# NANO100AN_v1 register map
File version: 1.0
Registers are 32-bit, read-write, reset 0x0 unless marked. A register's access mark holds for its fields unless they carry their own. Offsets are from the block's base; [hi:lo] are bit positions; {n}, {i} and the like mark numbered series; 'fields as' and 'values as' point back to an identical list.

## ADC — ADC Register Map
Base 0x400E0000
{0x0+4i} ADC_RESULT{i} ro (i=0..7) — A/D Result Register {i}
  [11:0] RSLT — A/D Conversion Result. This field contains 12 bits conversion result.
0x28 ADC_RESULT10 ro — A/D Result Register 10
  fields as ADC_RESULT0
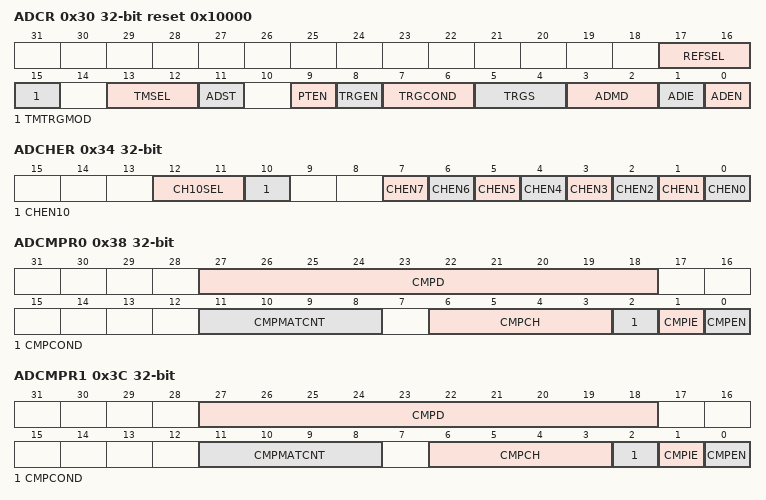
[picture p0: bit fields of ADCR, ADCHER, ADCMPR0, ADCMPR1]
0x30 ADCR reset 0x10000 — A/D Control Register
  [17:16] REFSEL — Reference Voltage Source Selection
    0=Select power as reference voltage; 1=Select VBG as reference voltage; 2=Select external voltage as reference voltage; 3=Ch7
  [15] TMTRGMOD — Timer Event Trigger ADC Conversion setting TMSEL to select timer event from timer0~3
    0=This function Disabled; 1=ADC Enabled by TIMER out event
  [13:12] TMSEL — Select A/D Enable Time-Out Source
    {v}=TMR{v} (v=0..3)
  [11] ADST — A/D Conversion Start. ADST bit can be set to 1 from two sources: software write and external pin STADC. ADST is cleared to 0 by hardware automatically at the end of single mode and single-cycle scan mode on specified channels. In continuous scan mode, A/D conversion is continuously performed sequentially unless software writes 0 to this bit or chip reset. Note: After ADC conversion done, SW needs to wait at least one ADC clock before to set this bit high again.
    0=Conversion stopped and A/D converter enter idle state; 1=Conversion starts
  [9] PTEN — PDMA Transfer Enable
    0=PDMA data transfer Disabled; 1=PDMA data transfer in ADC_RESULT 0~10 Enabled
  [8] TRGEN — External Trigger Enable. Enable or disable triggering of A/D conversion by external STADC pin.
    0=Disabled; 1=Enabled
  [7:6] TRGCOND — External Trigger Condition. These two bits decide external pin STADC trigger event is level or edge. The signal must be kept at stable state at least 8 PCLKs for level trigger and 4 PCLKs at high and low state.
    0=Low level; 1=High level; 2=Falling edge; 3=Rising edge
  [5:4] TRGS — Hardware Trigger Source. Software should disable TRGE and ADST before change TRGS. In hardware trigger mode, the ADST bit is set by the external trigger from STADC, However software has the highest priority to set or cleared ADST bit at any time.
    0=A/D conversion is started by external STADC pin
  [3:2] ADMD — A/D Converter Operation Mode
    0=Single conversion; 2=Single-cycle scan; 3=Continuous scan
  [1] ADIE — A/D Interrupt Enable. A/D conversion end interrupt request is generated if ADIE bit is set to 1.
    0=A/D interrupt function Disabled; 1=A/D interrupt function Enabled
  [0] ADEN — A/D Converter Enable. Before starting A/D conversion function, this bit should be set to 1. Clear it to 0 to disable A/D converter analog circuit power consumption.
    0=Disabled; 1=Enabled
0x34 ADCHER — A/D Channel Enable Register
  [12:11] CH10SEL — Select Channel10 Input
    0=Select VTEMP as channel10 input; 2=Select AVDD as channel10 input; 3=Select AVSS as channel10 input
  [10] CHEN10 — Analog Input Channel 10 Enable Control
    0=Disabled; 1=Enabled
  [7] CHEN7 — Analog Input Channel 7 Enable Control
    0=Disabled; 1=Enabled
  [6] CHEN6 — Anaslog Input Channel 6 Enable Control
    0=Disabled; 1=Enabled
  [n] CHEN{n} (n=1..5) — Analog Input Channel {n} Enable Control
    0=Disabled; 1=Enabled
  [0] CHEN0 — Analog Input Channel 0 Enable Control. If more than one channel in single mode is enabled by software, the least channel is converted and other enabled channels will be ignored.
    0=Disabled; 1=Enabled
0x38 ADCMPR0 — A/D Compare Register 0
  [27:18] CMPD — Comparison Data. The 12 bits data is used to compare with conversion result of specified channel. Software can use it to monitor the external analog input pin voltage variation in scan mode without imposing a load on software.
  [11:8] CMPMATCNT — Compare Match Count. When the specified A/D channel analog conversion result matches the compare condition defined by CMPCOND[2], the internal match counter will increase 1. When the internal counter reaches the value to (CMPMATCNT +1), the CMPF bit will be set.
  [6:3] CMPCH — Compare Channel Selection. Set this field to select which channel's result to be compared. Note: Valid setting of this field is channel 0~10.
  [2] CMPCOND — Compare Condition. Note: When the internal counter reaches the value to (CMPMATCNT +1), the CMPF (ADSR[2,1]) will be set.
    0=Set the compare condition as that when a 12-bit A/D conversion result is less than the 12-bit CMPD (ADCMPRx[27:16]), the internal match counter will increase one; 1=Set the compare condition as that when a 12-bit A/D conversion result is greater or equal to the 12-bit CMPD (ADCMPRx[27:16]), the internal match counter will increase by one
  [1] CMPIE — Compare Interrupt Enable. If the compare function is enabled and the compare condition matches the setting of CMPCOND and CMPMATCNT, CMPF (ADSR[2,1]) will be asserted, in the meanwhile, if CMPIE is set to 1, a compare interrupt request is generated.
    0=Compare function interrupt Disabled; 1=Compare function interrupt Enabled
  [0] CMPEN — Compare Enable. Set this bit to 1 to enable compare CMPD[11:0] with specified channel conversion result when converted data is loaded into ADC_RESULTx register. When this bit is set to 1, and CMPMATCNT is 0, the CMPF (ADSR[2,1]) will be set once the match is hit
    0=Compare Disabled; 1=Compare Enabled
0x3C ADCMPR1 — A/D Compare Register 1
  fields as ADCMPR0
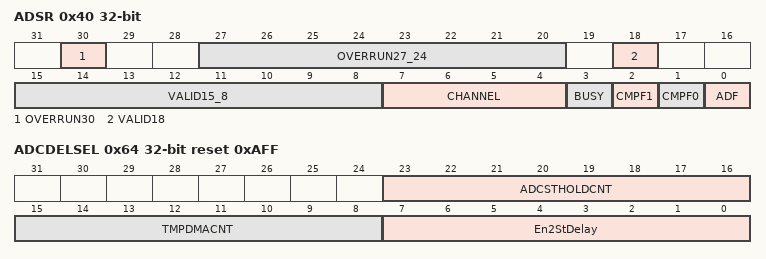
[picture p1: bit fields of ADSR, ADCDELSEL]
0x40 ADSR — A/D Status Register
  [30] OVERRUN30 — Over Run Flag. When VALID is high and ADC converts finish, this field will set to high. Note: This flag is for ADC_RESULT10
  [27:20] OVERRUN27_24 — Over Run Flag. When VALID is high and ADC converts finish, this field will set to high. Note: Those flag are for ADC_RESULT0~7
  [18] VALID18 — Data Valid Flag. After ADC converts finish, this field will set to high. This field will clear when ADC_RESULTx be read. Note: This flag is for ADC_RESULT10
  [15:8] VALID15_8 — Data Valid Flag. After ADC converts finish, this field will set to high. This field will clear when ADC_RESULTx be read. Note: Those flags are for ADC_RESULT0~7
  [7:4] CHANNEL ro — Current Conversion Channel (Read Only)
  [3] BUSY — BUSY/IDLE
    0=A/D converter is in idle state; 1=A/D converter is busy at conversion
  [2] CMPF1 — Compare Flag. When the selected channel A/D conversion result meets setting condition in ADCMPR1 then this bit is set to 1. And it is cleared by writing 1 to self. This flag can be cleared by writing 1 to it. Note: when this flag is set, the matching counter will be reset to 0,and continue to count when user write 1 to clear CMPF1
    0=Conversion result in ADC_RESULTx does not meet ADCMPR1 setting; 1=Conversion result in ADC_RESULTx meets ADCMPR1 setting
  [1] CMPF0 — Compare Flag. When the selected channel A/D conversion result meets setting condition in ADCMPR0 then this bit is set to 1. And it is cleared by writing 1 to self. This flag can be cleared by writing 1 to it. Note: when this flag is set, the matching counter will be reset to 0,and continue to count when user write 1 to clear CMPF0
    0=Conversion result in ADC_RESULTx does not meet ADCMPR0setting; 1=Conversion result in ADC_RESULTx meets ADCMPR0setting
  [0] ADF — A/D Conversion End Flag. A status flag that indicates the end of A/D conversion. ADF is set to 1 at these two conditions: When A/D conversion ends in single mode. When A/D conversion ends on all specified channels in scan mode. This flag can be cleared by writing 1 to it.
0x54 ADFCR — A/D FPGA Control Register+
0x60 ADPDMA ro — A/D PDMA Current Transfer Data Register
  [11:0] AD_PDMA — ADC PDMA Current Transfer Data Register (Read Only). When PDMA transferring, read this register can monitor current PDMA transfer data.
0x64 ADCDELSEL reset 0xAFF — PDMA Counter for Delay Time and PDMA Transfer Count and ADC Start Hold Counter
  [23:16] ADCSTHOLDCNT — ADC Start Hold Time Counter. This ADC start is the start signal from ADC controller to analog ADC, not the ADST in ADCR[11],. In Figure 517, when ADC start signal transition from high to low, the ADC reset signal will transition from low to high, at this moment the ADC hold the input analog single and stop holding when ADC start signal transition from low to high. The interval of the holding time is programmable by setting this register. ADC need ADC start signal to keep low level at least 2 ADC CLOCK in order to get converting result more accurately. Setting this register will change the interval in ADC CLOCK unit
  [15:8] TMPDMACNT — PDMA Count. When each time out event occur PDMA will transfer TMPDMACNT +1 ADC result in the amount of this register setting. Note: The total amount of PDMA transferring data should be set in PDMA byte count register. When PDMA finish is set, ADC will not be enabled and start transfer even though the time out event occur
  [7:0] En2StDelay — A/D Delay Time Select Register. Set this register to adjust the time interval (in PCLK unit )between start signal and enable signal of ADC. Note: The time interval is En2StDelay+1 PCLK cycle
